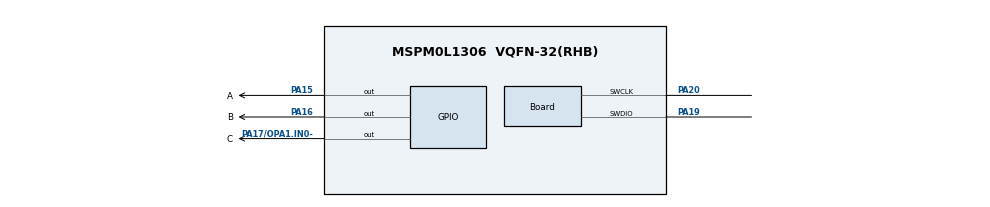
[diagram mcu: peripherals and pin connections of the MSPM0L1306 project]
//@cliArgs --device "MSPM0L130X" --package "VQFN-32(RHB)" --part "Default"
//@v2CliArgs --device "MSPM0L1306" --package "VQFN-32(RHB)"
// @cliArgs --board /ti/boards/LP_MSPM0L1306 --rtos nortos

/**
 * Import the modules used in this configuration.
 */
const Board  = scripting.addModule("/ti/driverlib/Board");
const COMP   = scripting.addModule("/ti/driverlib/COMP", {}, false);
const COMP1  = COMP.addInstance();
const GPIO   = scripting.addModule("/ti/driverlib/GPIO", {}, false);
const GPIO1  = GPIO.addInstance();
const SYSCTL = scripting.addModule("/ti/driverlib/SYSCTL");

/**
 * Write custom configuration values to the imported modules.
 */
Board.InitPriority8               = "/ti/driverlib/VREF";
Board.peripheral.$assign          = "DEBUGSS";
Board.peripheral.swclkPin.$assign = "PA20";
Board.peripheral.swdioPin.$assign = "PA19";

COMP1.selectOutputFilter             = "DL_COMP_FILTER_DELAY_1200";
COMP1.enableOutputFilter             = true;
COMP1.hysteresis                     = "DL_COMP_HYSTERESIS_30";
COMP1.controlSelect                  = "DL_COMP_DAC_CONTROL_SW";
COMP1.$name                          = "COMP";
COMP1.vSource                        = "DL_COMP_REF_SOURCE_VDDA_DAC";
COMP1.negChannel                     = "DL_COMP_IMSEL_CHANNEL_1";
COMP1.channelEnable                  = ["POS"];
COMP1.terminalSelect                 = "DL_COMP_REF_TERMINAL_SELECT_NEG";
COMP1.setDACCode0                    = 0x27;
COMP1.peripheral.$assign             = "COMP0";
COMP1.peripheral.compPinPos0.$assign = "PA26";
COMP1.compPinPos0Config.$name        = "ti_driverlib_gpio_GPIOPinGeneric0";

GPIO1.$name                          = "COMP_OUTPUT";
GPIO1.associatedPins.create(3);
GPIO1.associatedPins[0].assignedPort = "PORTA";
GPIO1.associatedPins[0].$name        = "A";
GPIO1.associatedPins[0].pin.$assign  = "PA15";
GPIO1.associatedPins[1].$name        = "B";
GPIO1.associatedPins[1].pin.$assign  = "PA16";
GPIO1.associatedPins[2].$name        = "C";
GPIO1.associatedPins[2].pin.$assign  = "PA17/OPA1.IN0-";

SYSCTL.clockTreeEn = true;

/**
 * These are the reserved peripherals and settings in this configuration
 */
const iGPIO1        = scripting.addPeripheral("GPIO");
iGPIO1.$numPins     = 2;
iGPIO1["0"].$assign = "PA23";
iGPIO1["1"].$assign = "PA27";
iGPIO1.$name        = "COMP_BLOCK";
